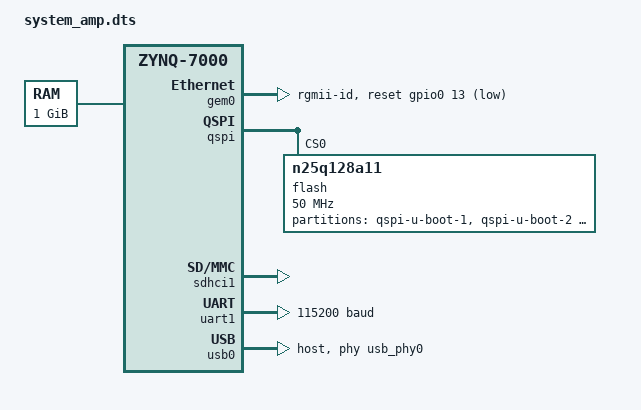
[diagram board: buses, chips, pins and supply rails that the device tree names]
/*
 * CAUTION: This file is automatically generated by Xilinx.
 * Version:  
 * Today is: Sat May 06 10:43:22 2017
*/

/dts-v1/;
/include/ "zynq-7000.dtsi"
/include/ "pl.dtsi"
/ {
    cpus {
        cpu@0 {
            operating-points = <666666 1000000 333333 1000000>;
        };
    };

    chosen {
        stdout-path = "serial1:115200n8";
    };

    aliases {
        ethernet0 = &gem0;
        serial1 = &uart1;
        spi0 = &qspi;
    };

    memory@0 {
        device_type = "memory";
        reg = <0x0 0x40000000>;
    };
    
    usb_phy0: phy0@e0002000 {
       compatible = "ulpi-phy";
       #phy-cells = <0>;
       reg = <0xe0002000 0x1000>;
       view-port = <0x170>;
       drv-vbus;
       reset-gpios = <&gpio0 0 1>;
       reset-delay-us = <20000>;
    };

    amba {
        elf_ddr_0: ddr@100000 {
            compatible = "mmio-sram";
            reg = <0x100000 0x100000>;
        };
    };

    remoteproc0: remoteproc {
        compatible = "xlnx,zynq_remoteproc";
        firmware = "firmware";
        vring0 = <0xf>;
        vring1 = <0xe>;
        sram_0 = <&elf_ddr_0>;
    };
    
    swd_gpio0 {
        label = "swd-gpio0";
        gpios = <&gpio0 42 0>;
    };  
    
    swd_gpio1 {
        label = "swd-gpio1";
        gpios = <&gpio0 43 0>;
    }; 
};

&gem0 {
    local-mac-address = [00 0a 35 00 01 22];
    phy-mode = "rgmii-id";
    status = "okay";
    xlnx,ptp-enet-clock = <0x69f6bcb>;
    reset-gpios = <&gpio0 13 1>;
    reset-delay-us = <20000>;
};

&gpio0 {
    emio-gpio-width = <64>;
    gpio-mask-high = <0x0>;
    gpio-mask-low = <0x5600>;
};

&i2c0 {
    clock-frequency = <100000>;
    status = "disabled";
};

&i2c1 {
    clock-frequency = <100000>;
    status = "disabled";
};

&intc {
    num_cpus = <2>;
    num_interrupts = <96>;
};

&qspi {
    status = "okay";
    is-dual = <0>;
    num-cs = <1>;
        flash@0 {
                compatible = "n25q128a11";
                reg = <0x0>;
                spi-tx-bus-width = <1>;
                spi-rx-bus-width = <4>;
                spi-max-frequency = <50000000>;
                #address-cells = <1>;
                #size-cells = <1>;

                partition@qspi-u-boot-1 {
                label = "qspi-u-boot-1";
                reg = <0x0 0x200000>;
                };
                partition@qspi-u-boot-2 {
                    label = "qspi-u-boot-2";
                    reg = <0x200000 0x200000>;
                };
                partition@qspi-u-boot-env {
                    label = "qspi-u-boot-env";
                    reg = <0x400000 0x100000>;
                };
                partition@qspi-bitstream {
                    label = "qspi-bitstream";
                    reg = <0x500000 0x500000>;
                };
                partition@qspi-uImage {
                    label = "qspi-uImage";
                    reg = <0xA00000 0x500000>;
                };
                partition@qspi-devicetree {
                    label = "qspi-devicetree";
                    reg = <0xF00000 0x100000>;
                };
        };
};

&sdhci0 {
    status = "disabled";
    xlnx,has-cd = <0x1>;
    xlnx,has-power = <0x0>;
    xlnx,has-wp = <0x1>;
};

&sdhci1 {
    status = "okay";
    xlnx,has-cd = <0x1>;
    xlnx,has-power = <0x0>;
    xlnx,has-wp = <0x1>;
};

&uart0 {
    status = "disabled";
};

&uart1 {
    current-speed = <115200>;
    device_type = "serial";
    port-number = <0>;
    status = "okay";
};

&usb0 {
    dr_mode = "host";
    status = "okay";
    usb-reset = <&gpio0 0 0>;
    usb-phy = <&usb_phy0>;
};

&clkc {
    fclk-enable = <0x3>;
    ps-clk-frequency = <33333333>;
};

&global_timer {
    status = "disabled";
};

